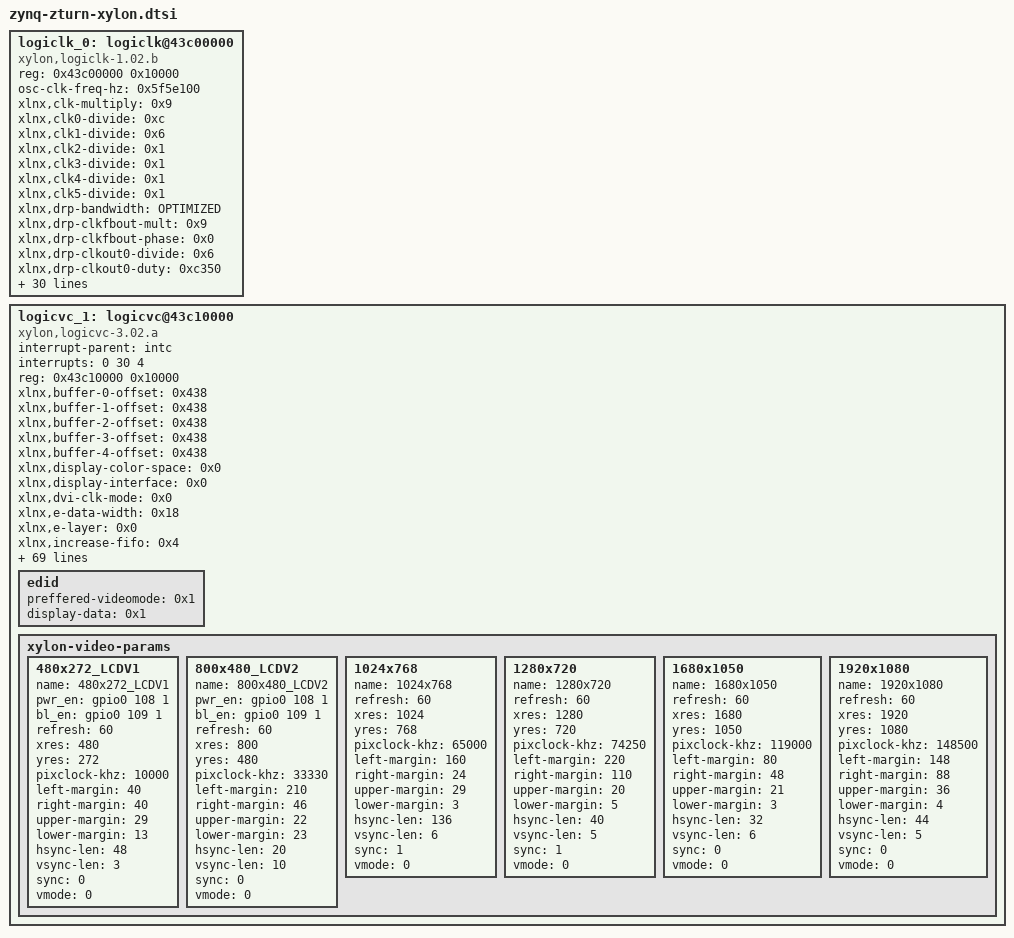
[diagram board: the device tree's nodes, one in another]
logiclk_0: logiclk@43c00000 {
	compatible = "xylon,logiclk-1.02.b";
	reg = <0x43c00000 0x10000>;
	osc-clk-freq-hz = <0x5f5e100>;
	xlnx,clk-multiply = <0x9>;
	xlnx,clk0-divide = <0xc>;
	xlnx,clk1-divide = <0x6>;
	xlnx,clk2-divide = <0x1>;
	xlnx,clk3-divide = <0x1>;
	xlnx,clk4-divide = <0x1>;
	xlnx,clk5-divide = <0x1>;
	xlnx,drp-bandwidth = "OPTIMIZED";
	xlnx,drp-clkfbout-mult = <0x9>;
	xlnx,drp-clkfbout-phase = <0x0>;
	xlnx,drp-clkout0-divide = <0x6>;
	xlnx,drp-clkout0-duty = <0xc350>;
	xlnx,drp-clkout0-phase = <0x0>;
	xlnx,drp-clkout1-divide = <0x1>;
	xlnx,drp-clkout1-duty = <0xc350>;
	xlnx,drp-clkout1-phase = <0x0>;
	xlnx,drp-clkout2-divide = <0x1>;
	xlnx,drp-clkout2-duty = <0xc350>;
	xlnx,drp-clkout2-phase = <0x0>;
	xlnx,drp-clkout3-divide = <0x1>;
	xlnx,drp-clkout3-duty = <0xc350>;
	xlnx,drp-clkout3-phase = <0x0>;
	xlnx,drp-clkout4-divide = <0x1>;
	xlnx,drp-clkout4-duty = <0xc350>;
	xlnx,drp-clkout4-phase = <0x0>;
	xlnx,drp-clkout5-divide = <0x1>;
	xlnx,drp-clkout5-duty = <0xc350>;
	xlnx,drp-clkout5-phase = <0x0>;
	xlnx,drp-divclk-divide = <0x1>;
	xlnx,ip-license-type = <0x1>;
	xlnx,ip-major-revision = <0x1>;
	xlnx,ip-minor-revision = <0x2>;
	xlnx,ip-patch-level = <0x1>;
	xlnx,regs-interface = <0x2>;
	xlnx,rst-polarity = <0x0>;
	xlnx,splb-awidth = <0x20>;
	xlnx,splb-dwidth = <0x20>;
	xlnx,splb-mid-width = <0x1>;
	xlnx,splb-native-dwidth = <0x20>;
	xlnx,splb-num-masters = <0x2>;
	xlnx,use-clk-drp = <0x1>;
	xlnx,use-vlink-clk = <0x0>;
} ;

logicvc_1: logicvc@43c10000 {
	compatible = "xylon,logicvc-3.02.a";
	interrupt-parent = <&intc>;
	interrupts = <0 30 4>;
	reg = <0x43c10000 0x10000>;
	xlnx,buffer-0-offset = <0x438>;
	xlnx,buffer-1-offset = <0x438>;
	xlnx,buffer-2-offset = <0x438>;
	xlnx,buffer-3-offset = <0x438>;
	xlnx,buffer-4-offset = <0x438>;
	xlnx,display-color-space = <0x0>;
	xlnx,display-interface = <0x0>;
	xlnx,dvi-clk-mode = <0x0>;
	xlnx,e-data-width = <0x18>;
	xlnx,e-layer = <0x0>;
	xlnx,increase-fifo = <0x4>;
	xlnx,ip-license-check = <0x1>;
	xlnx,ip-license-type = <0x1>;
	xlnx,ip-major-revision = <0x3>;
	xlnx,ip-minor-revision = <0x2>;
	xlnx,ip-patch-level = <0x0>;
	xlnx,ip-time-before-break = <0x1>;
	xlnx,layer-0-alpha-mode = <0x1>;
	xlnx,layer-0-data-width = <0x18>;
	xlnx,layer-0-offset = <0x1c7a>;
	xlnx,layer-0-type = <0x0>;
	xlnx,layer-1-alpha-mode = <0x0>;
	xlnx,layer-1-data-width = <0x18>;
	xlnx,layer-1-offset = <0xfd2>;
	xlnx,layer-1-type = <0x0>;
	xlnx,layer-2-alpha-mode = <0x0>;
	xlnx,layer-2-data-width = <0x18>;
	xlnx,layer-2-offset = <0x0>;
	xlnx,layer-2-type = <0x0>;
	xlnx,layer-3-alpha-mode = <0x3>;
	xlnx,layer-3-data-width = <0x8>;
	xlnx,layer-3-offset = <0x32a0>;
	xlnx,layer-3-type = <0x0>;
	xlnx,layer-4-alpha-mode = <0x0>;
	xlnx,layer-4-data-width = <0x18>;
	xlnx,layer-4-offset = <0x2000>;
	xlnx,layer-4-type = <0x0>;
	xlnx,lvds-data-width = <0x4>;
	xlnx,mem-burst = <0x4>;
	xlnx,mem-byte-swap = <0x0>;
	xlnx,mem-little-endian = <0x1>;
	xlnx,mplb-awidth = <0x20>;
	xlnx,mplb-dwidth = <0x40>;
	xlnx,mplb-num-masters = <0x8>;
	xlnx,mplb-priority = <0x3>;
	xlnx,mplb-smallest-slave = <0x20>;
	xlnx,num-of-layers = <0x3>;
	xlnx,opb-awidth = <0x20>;
	xlnx,opb-dwidth = <0x20>;
	xlnx,pixel-data-width = <0x10>;
	xlnx,little-endian = <0x1>;
	xlnx,readable-regs = <0x1>;
	xlnx,reg-byte-swap = <0x0>;
	xlnx,regs-interface = <0x2>;
	xlnx,row-stride = <0x800>;
	xlnx,splb-awidth = <0x20>;
	xlnx,splb-dwidth = <0x20>;
	xlnx,splb-mid-width = <0x1>;
	xlnx,splb-native-dwidth = <0x20>;
	xlnx,splb-num-masters = <0x2>;
	xlnx,use-e-parallel-input = <0x0>;
	xlnx,use-e-vclk-bufgmux = <0x0>;
	xlnx,use-multiplier = <0x2>;
	xlnx,vmem-baseaddr = <0x30000000>;
	xlnx,vmem-highaddr = <0x3fffffff>;
	pixel-clock-source = <2>;
	pixel-data-invert = <0>;
	pixel-clock-active-high = <0>;
	pixel-component-format = "ARGB";
	pixel-component-layer = <0x0 0x1 0x2>;
	xlnx,use-vclk2 = <0x1>;
	xlnx,use-xtreme-dsp = <0x1>;
	xlnx,vclk-period = <0x61a8>;
	xlnx,vmem-interface = <0x2>;
	xlnx,xcolor = <0x0>;
	xlnx,xmb-data-bus-width = <0x40>;
	xlnx,use-background = <0x1>;
	xlnx,use-size-position = <0x1>;
	active-layer = <0x1>;
	videomode = "1920x1080";
	edid {
		preffered-videomode = <0x1>;
		display-data = <0x1>;
   };

	xylon-video-params {	
		480x272_LCDV1{
			name = "480x272_LCDV1";
			pwr_en = <&gpio0 108 1>;
			bl_en = <&gpio0 109 1>;			
			refresh = <60>;
			xres = <480>;
			yres = <272>;
			pixclock-khz = <10000>;
			left-margin = <40>;
			right-margin = <40>;
			upper-margin = <29>;
			lower-margin = <13>;
			hsync-len = <48>;
			vsync-len = <3>;
			sync = <0>;
			vmode = <0>;
		};
		800x480_LCDV2 {
			name = "800x480_LCDV2";
			pwr_en = <&gpio0 108 1>;
			bl_en = <&gpio0 109 1>;
			refresh = <60>;
			xres = <800>;
			yres = <480>;
			pixclock-khz = <33330>;
			left-margin = <210>;
			right-margin = <46>;
			upper-margin = <22>;
			lower-margin = <23>;
			hsync-len = <20>;
			vsync-len = <10>;
			sync = <0>;
			vmode = <0>;
		};
		1024x768 {
			name = "1024x768";
			refresh = <60>;
			xres = <1024>;
			yres = <768>;
			pixclock-khz = <65000>;
			left-margin = <160>;
			right-margin = <24>;
			upper-margin = <29>;
			lower-margin = <3>;
			hsync-len = <136>;
			vsync-len = <6>;
			sync = <1>;
			vmode = <0>;
		};
		1280x720 {
			name = "1280x720";
			refresh = <60>;
			xres = <1280>;
			yres = <720>;
			pixclock-khz = <74250>;
			left-margin = <220>;
			right-margin = <110>;
			upper-margin = <20>;
			lower-margin = <5>;
			hsync-len = <40>;
			vsync-len = <5>;
			sync = <1>;
			vmode = <0>;
		};
		1680x1050 {
			name = "1680x1050";
			refresh = <60>;
			xres = <1680>;
			yres = <1050>;
			pixclock-khz = <119000>;
			left-margin = <80>;
			right-margin = <48>;
			upper-margin = <21>;
			lower-margin = <3>;
			hsync-len = <32>;
			vsync-len = <6>;
			sync = <0>;
			vmode = <0>;
		};
		1920x1080 {
			name = "1920x1080";
			refresh = <60>;
			xres = <1920>;
			yres = <1080>;
			pixclock-khz = <148500>;
			left-margin = <148>;
			right-margin = <88>;
			upper-margin = <36>;
			lower-margin = <4>;
			hsync-len = <44>;
			vsync-len = <5>;
			sync = <0>;
			vmode = <0>;
		};
	};
} ;
